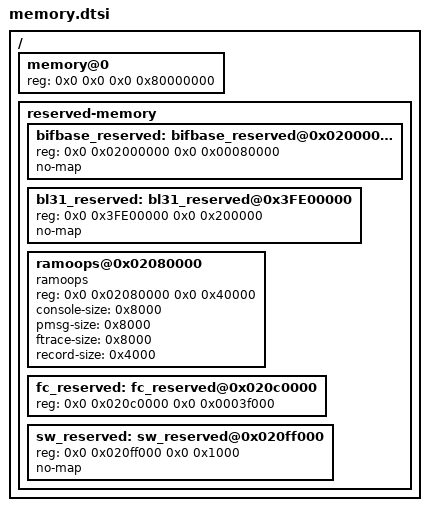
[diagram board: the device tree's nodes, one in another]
/ {

	/* real total memory is set in uboot, not here*/
	memory@0 {
		device_type = "memory";
		reg = <0x0 0x0 0x0 0x80000000>;
	};

	reserved-memory {
		#address-cells = <2>;
		#size-cells = <2>;
		ranges;

		/*Reserved 512K memory for bifbase*/
		bifbase_reserved: bifbase_reserved@0x02000000 {
			reg = <0x0 0x02000000 0x0 0x00080000>;
			no-map;
		};

		/*Reserved 2MB memory for BL31*/
		bl31_reserved: bl31_reserved@0x3FE00000 {
			reg = <0x0 0x3FE00000 0x0 0x200000>;
			no-map;
		};
		
		/*Reserved 256K memory pstore */
		ramoops@0x02080000 {
			compatible = "ramoops";
			reg = <0x0 0x02080000 0x0 0x40000>;
			console-size = <0x8000>;
			pmsg-size = <0x8000>;
			ftrace-size = <0x8000>;
			record-size = <0x4000>;
		};

		/* Reserved 192K memory for function call */
		fc_reserved: fc_reserved@0x020c0000 {
			reg = <0x0 0x020c0000 0x0 0x0003f000>;
		};

		/* Reserved 4K memory for swinfo */
		sw_reserved: sw_reserved@0x020ff000 {
			reg = <0x0 0x020ff000 0x0 0x1000>;
			no-map;
		};

		/*Note: Reserved 16M shared memory for uboot: 0x02100000*/

	};
};
